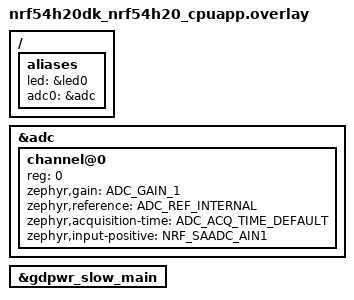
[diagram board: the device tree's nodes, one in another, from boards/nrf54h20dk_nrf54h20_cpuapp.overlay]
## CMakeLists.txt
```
#
# Copyright (c) 2024 Nordic Semiconductor
#
# SPDX-License-Identifier: LicenseRef-Nordic-5-Clause
#

cmake_minimum_required(VERSION 3.13.1)
find_package(Zephyr REQUIRED HINTS $ENV{ZEPHYR_BASE})
zephyr_include_directories(include)

project(adc_async)

target_sources(app PRIVATE ./../common/main.c)
target_sources(app PRIVATE src/driver_test.c)
```

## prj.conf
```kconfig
# Drivers and peripherals
CONFIG_ADC=y
CONFIG_ADC_ASYNC=y

# Enable runtime power management for peripheral
CONFIG_PM_DEVICE=y
CONFIG_PM_DEVICE_RUNTIME=y

CONFIG_PM=y
CONFIG_PM_S2RAM=y
CONFIG_POWEROFF=y
CONFIG_PM_S2RAM_CUSTOM_MARKING=y
CONFIG_CONSOLE=n
CONFIG_UART_CONSOLE=n
CONFIG_SERIAL=n
CONFIG_BOOT_BANNER=n
```

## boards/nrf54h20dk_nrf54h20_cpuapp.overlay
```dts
/ {
	aliases {
		led = &led0;
		/delete-property/ led1;
		adc0 = &adc;
	};
};

/delete-node/ &led1;

&adc {
	#address-cells = <1>;
	#size-cells = <0>;

	channel@0 {
		reg = <0>;
		zephyr,gain = "ADC_GAIN_1";
		zephyr,reference = "ADC_REF_INTERNAL";
		zephyr,acquisition-time = <ADC_ACQ_TIME_DEFAULT>;
		zephyr,input-positive = <NRF_SAADC_AIN1>;
	};

};

&gdpwr_slow_main {
	/delete-property/zephyr,pm-device-runtime-auto;
};
```

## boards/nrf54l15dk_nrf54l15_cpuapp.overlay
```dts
/ {
	aliases {
		led = &button3;
		adc0 = &adc;
	};
};

&adc {
	#address-cells = <1>;
	#size-cells = <0>;

	channel@0 {
		reg = <0>;
		zephyr,gain = "ADC_GAIN_1";
		zephyr,reference = "ADC_REF_INTERNAL";
		zephyr,acquisition-time = <ADC_ACQ_TIME_DEFAULT>;
		zephyr,input-positive = <NRF_SAADC_AIN1>;
	};

};
```

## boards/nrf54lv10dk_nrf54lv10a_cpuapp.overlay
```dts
/ {
	aliases {
		led = &led0;
		/delete-property/ led1;
		adc0 = &adc;
	};
};

/delete-node/ &led1;

&adc {
	#address-cells = <1>;
	#size-cells = <0>;
	status = "okay";

	channel@0 {
		reg = <0>;
		zephyr,gain = "ADC_GAIN_1";
		zephyr,reference = "ADC_REF_INTERNAL";
		zephyr,acquisition-time = <ADC_ACQ_TIME_DEFAULT>;
		zephyr,input-positive = <NRF_SAADC_AIN7>;  /* P1.12 */
		zephyr,resolution = <14>;
	};
};
```

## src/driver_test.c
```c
/*
 * Copyright (c) 2024 Nordic Semiconductor ASA
 *
 * SPDX-License-Identifier: LicenseRef-Nordic-5-Clause
 */

#include <zephyr/drivers/adc.h>
#include <zephyr/kernel.h>
#define ADC_NODE DT_ALIAS(adc0)
static const struct device *adc = DEVICE_DT_GET(ADC_NODE);

/* Get the number of channels defined on the DTS. */
static const struct adc_channel_cfg channel_cfgs[] = {
DT_FOREACH_CHILD_SEP(ADC_NODE, ADC_CHANNEL_CFG_DT, (,))};

void thread_definition(void)
{
	uint16_t channel_reading[5];
	int ret;

	/* Options for the sequence sampling. */
	const struct adc_sequence_options options = {
		.extra_samplings = 1,
		.interval_us = 0,
	};

	struct adc_sequence sequence = {
		.buffer = channel_reading,
		/* buffer size in bytes, not number of samples */
		.buffer_size = sizeof(channel_reading),
		.resolution = 12,
		.options = &options,
		.channels = 1,
	};

	ret = adc_channel_setup(adc, &channel_cfgs[0]);
	if (ret < 0) {
		printk("Issue with setting up channel, terminating thread.");
		return;
	}
	while (1) {
		ret = adc_read_async(adc, &sequence, NULL);
		if (ret < 0) {
			printk("Issue wih reading voltage, terminating thread.");
			return;
		}
	};
};
```
